# A8137M register map
Vendor: Amiccom Electronics Co., Ltd.; Series: A8137M; File version: 1.0
CPU: CM0 r0p0, little endian, no MPU, no FPU, 2 interrupt priority bits
Registers are 32-bit, read-write, reset 0x0 unless marked. A register's access mark holds for its fields unless they carry their own. Offsets are from the block's base; [hi:lo] are bit positions; {n}, {i} and the like mark numbered series.

## GPIO0 — General Purpose I/O
Base 0x40010000
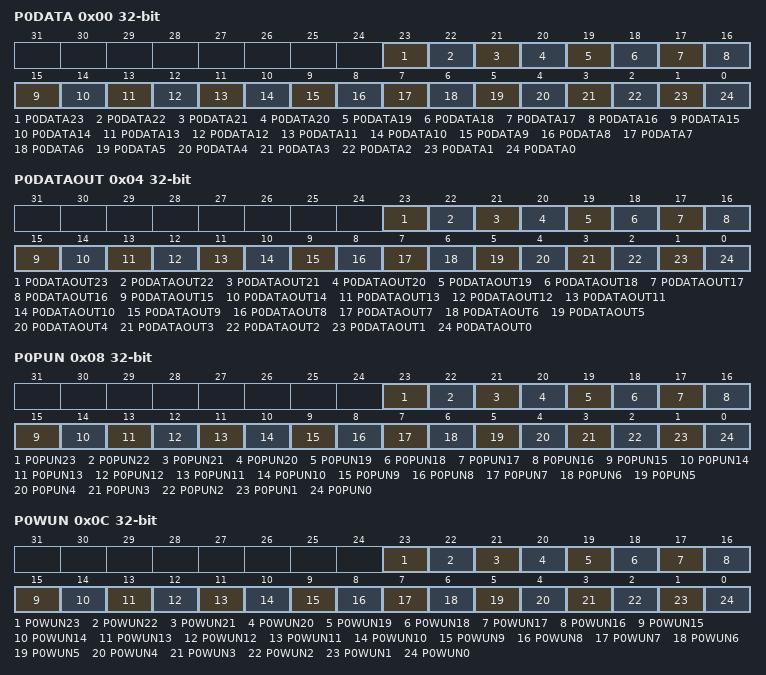
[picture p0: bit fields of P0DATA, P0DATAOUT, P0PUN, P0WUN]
0x00 P0DATA — Port 0 Data Register
  [23] P0DATA23 — Data of GPIO0.23
    0=GPIO0.23 is 0; 1=GPIO0.23 is 1
  [22] P0DATA22 — Data of GPIO0.22
    0=GPIO0.22 is 0; 1=GPIO0.22 is 1
  [21] P0DATA21 — Data of GPIO0.21
    0=GPIO0.21 is 0; 1=GPIO0.21 is 1
  [20] P0DATA20 — Data of GPIO0.20
    0=GPIO0.20 is 0; 1=GPIO0.20 is 1
  [19] P0DATA19 — Data of GPIO0.19
    0=GPIO0.19 is 0; 1=GPIO0.19 is 1
  [18] P0DATA18 — Data of GPIO0.18
    0=GPIO0.18 is 0; 1=GPIO0.18 is 1
  [17] P0DATA17 — Data of GPIO0.17
    0=GPIO0.17 is 0; 1=GPIO0.17 is 1
  [16] P0DATA16 — Data of GPIO0.16
    0=GPIO0.16 is 0; 1=GPIO0.16 is 1
  [15] P0DATA15 — Data of GPIO0.15
    0=GPIO0.15 is 0; 1=GPIO0.15 is 1
  [14] P0DATA14 — Data of GPIO0.14
    0=GPIO0.14 is 0; 1=GPIO0.14 is 1
  [13] P0DATA13 — Data of GPIO0.13
    0=GPIO0.13 is 0; 1=GPIO0.13 is 1
  [12] P0DATA12 — Data of GPIO0.12
    0=GPIO0.12 is 0; 1=GPIO0.12 is 1
  [11] P0DATA11 — Data of GPIO0.11
    0=GPIO0.11 is 0; 1=GPIO0.11 is 1
  [10] P0DATA10 — Data of GPIO0.10
    0=GPIO0.10 is 0; 1=GPIO0.10 is 1
  [9] P0DATA9 — Data of GPIO0.9
    0=GPIO0.9 is 0; 1=GPIO0.9 is 1
  [8] P0DATA8 — Data of GPIO0.8
    0=GPIO0.8 is 0; 1=GPIO0.8 is 1
  [7] P0DATA7 — Data of GPIO0.7
    0=GPIO0.7 is 0; 1=GPIO0.7 is 1
  [6] P0DATA6 — Data of GPIO0.6
    0=GPIO0.6 is 0; 1=GPIO0.6 is 1
  [5] P0DATA5 — Data of GPIO0.5
    0=GPIO0.5 is 0; 1=GPIO0.5 is 1
  [4] P0DATA4 — Data of GPIO0.4
    0=GPIO0.4 is 0; 1=GPIO0.4 is 1
  [3] P0DATA3 — Data of GPIO0.3
    0=GPIO0.3 is 0; 1=GPIO0.3 is 1
  [2] P0DATA2 — Data of GPIO0.2
    0=GPIO0.2 is 0; 1=GPIO0.2 is 1
  [1] P0DATA1 — Data of GPIO0.1
    0=GPIO0.1 is 0; 1=GPIO0.1 is 1
  [0] P0DATA0 — Data of GPIO0.0
    0=GPIO0.0 is 0; 1=GPIO0.0 is 1
0x00 P0DATA_PIN (reset mask 0xFFFFFF) (alternate view of P0DATA) — Port 0 Data Register access by Pin
0x04 P0DATAOUT — Port 0 Data Out Register
  [23] P0DATAOUT23 — Data Out of GPIO0.23
    0=GPIO0.23 is 0; 1=GPIO0.23 is 1
  [22] P0DATAOUT22 — Data Out of GPIO0.22
    0=GPIO0.22 is 0; 1=GPIO0.22 is 1
  [21] P0DATAOUT21 — Data Out of GPIO0.21
    0=GPIO0.21 is 0; 1=GPIO0.21 is 1
  [20] P0DATAOUT20 — Data Out of GPIO0.20
    0=GPIO0.20 is 0; 1=GPIO0.20 is 1
  [19] P0DATAOUT19 — Data Out of GPIO0.19
    0=GPIO0.19 is 0; 1=GPIO0.19 is 1
  [18] P0DATAOUT18 — Data Out of GPIO0.18
    0=GPIO0.18 is 0; 1=GPIO0.18 is 1
  [17] P0DATAOUT17 — Data Out of GPIO0.17
    0=GPIO0.17 is 0; 1=GPIO0.17 is 1
  [16] P0DATAOUT16 — Data Out of GPIO0.16
    0=GPIO0.16 is 0; 1=GPIO0.16 is 1
  [15] P0DATAOUT15 — Data Out of GPIO0.15
    0=GPIO0.15 is 0; 1=GPIO0.15 is 1
  [14] P0DATAOUT14 — Data Out of GPIO0.14
    0=GPIO0.14 is 0; 1=GPIO0.14 is 1
  [13] P0DATAOUT13 — Data Out of GPIO0.13
    0=GPIO0.13 is 0; 1=GPIO0.13 is 1
  [12] P0DATAOUT12 — Data Out of GPIO0.12
    0=GPIO0.12 is 0; 1=GPIO0.12 is 1
  [11] P0DATAOUT11 — Data Out of GPIO0.11
    0=GPIO0.11 is 0; 1=GPIO0.11 is 1
  [10] P0DATAOUT10 — Data Out of GPIO0.10
    0=GPIO0.10 is 0; 1=GPIO0.10 is 1
  [9] P0DATAOUT9 — Data Out of GPIO0.9
    0=GPIO0.9 is 0; 1=GPIO0.9 is 1
  [8] P0DATAOUT8 — Data Out of GPIO0.8
    0=GPIO0.8 is 0; 1=GPIO0.8 is 1
  [7] P0DATAOUT7 — Data Out of GPIO0.7
    0=GPIO0.7 is 0; 1=GPIO0.7 is 1
  [6] P0DATAOUT6 — Data Out of GPIO0.6
    0=GPIO0.6 is 0; 1=GPIO0.6 is 1
  [5] P0DATAOUT5 — Data Out of GPIO0.5
    0=GPIO0.5 is 0; 1=GPIO0.5 is 1
  [4] P0DATAOUT4 — Data Out of GPIO0.4
    0=GPIO0.4 is 0; 1=GPIO0.4 is 1
  [3] P0DATAOUT3 — Data Out of GPIO0.3
    0=GPIO0.3 is 0; 1=GPIO0.3 is 1
  [2] P0DATAOUT2 — Data Out of GPIO0.2
    0=GPIO0.2 is 0; 1=GPIO0.2 is 1
  [1] P0DATAOUT1 — Data Out of GPIO0.1
    0=GPIO0.1 is 0; 1=GPIO0.1 is 1
  [0] P0DATAOUT0 — Data Out of GPIO0.0
    0=GPIO0.0 is 0; 1=GPIO0.0 is 1
0x04 P0DATAOUT_PIN (reset mask 0xFFFFFF) (alternate view of P0DATAOUT) — Port 0 Data Out Register access by Pin
0x08 P0PUN — Port 0 Pull Up Not Register
  [23] P0PUN23 — Pull Up of GPIO0.23
    0=Pull Up of GPIO0.23 is enable; 1=Pull Up of GPIO0.23 is disable
  [22] P0PUN22 — Pull Up of GPIO0.22
    0=Pull Up of GPIO0.22 is enable; 1=Pull Up of GPIO0.22 is disable
  [21] P0PUN21 — Pull Up of GPIO0.21
    0=Pull Up of GPIO0.21 is enable; 1=Pull Up of GPIO0.21 is disable
  [20] P0PUN20 — Pull Up of GPIO0.20
    0=Pull Up of GPIO0.20 is enable; 1=Pull Up of GPIO0.20 is disable
  [19] P0PUN19 — Pull Up of GPIO0.19
    0=Pull Up of GPIO0.19 is enable; 1=Pull Up of GPIO0.19 is disable
  [18] P0PUN18 — Pull Up of GPIO0.18
    0=Pull Up of GPIO0.18 is enable; 1=Pull Up of GPIO0.18 is disable
  [17] P0PUN17 — Pull Up of GPIO0.17
    0=Pull Up of GPIO0.17 is enable; 1=Pull Up of GPIO0.17 is disable
  [16] P0PUN16 — Pull Up of GPIO0.16
    0=Pull Up of GPIO0.16 is enable; 1=Pull Up of GPIO0.16 is disable
  [15] P0PUN15 — Pull Up of GPIO0.15
    0=Pull Up of GPIO0.15 is enable; 1=Pull Up of GPIO0.15 is disable
  [14] P0PUN14 — Pull Up of GPIO0.14
    0=Pull Up of GPIO0.14 is enable; 1=Pull Up of GPIO0.14 is disable
  [13] P0PUN13 — Pull Up of GPIO0.13
    0=Pull Up of GPIO0.13 is enable; 1=Pull Up of GPIO0.13 is disable
  [12] P0PUN12 — Pull Up of GPIO0.12
    0=Pull Up of GPIO0.12 is enable; 1=Pull Up of GPIO0.12 is disable
  [11] P0PUN11 — Pull Up of GPIO0.11
    0=Pull Up of GPIO0.11 is enable; 1=Pull Up of GPIO0.11 is disable
  [10] P0PUN10 — Pull Up of GPIO0.10
    0=Pull Up of GPIO0.10 is enable; 1=Pull Up of GPIO0.10 is disable
  [9] P0PUN9 — Pull Up of GPIO0.9
    0=Pull Up of GPIO0.9 is enable; 1=Pull Up of GPIO0.9 is disable
  [8] P0PUN8 — Pull Up of GPIO0.8
    0=Pull Up of GPIO0.8 is enable; 1=Pull Up of GPIO0.8 is disable
  [7] P0PUN7 — Pull Up of GPIO0.7
    0=Pull Up of GPIO0.7 is enable; 1=Pull Up of GPIO0.7 is disable
  [6] P0PUN6 — Pull Up of GPIO0.6
    0=Pull Up of GPIO0.6 is enable; 1=Pull Up of GPIO0.6 is disable
  [5] P0PUN5 — Pull Up of GPIO0.5
    0=Pull Up of GPIO0.5 is enable; 1=Pull Up of GPIO0.5 is disable
  [4] P0PUN4 — Pull Up of GPIO0.4
    0=Pull Up of GPIO0.4 is enable; 1=Pull Up of GPIO0.4 is disable
  [3] P0PUN3 — Pull Up of GPIO0.3
    0=Pull Up of GPIO0.3 is enable; 1=Pull Up of GPIO0.3 is disable
  [2] P0PUN2 — Pull Up of GPIO0.2
    0=Pull Up of GPIO0.2 is enable; 1=Pull Up of GPIO0.2 is disable
  [1] P0PUN1 — Pull Up of GPIO0.1
    0=Pull Up of GPIO0.1 is enable; 1=Pull Up of GPIO0.1 is disable
  [0] P0PUN0 — Pull Up of GPIO0.0
    0=Pull Up of GPIO0.0 is enable; 1=Pull Up of GPIO0.0 is disable
0x08 P0PUN_PIN (reset mask 0xFFFFFF) (alternate view of P0PUN) — Port 0 Pull Up Not Register access by Pin
0x0C P0WUN — Port 0 Wakeup Enable Not Register
  [23] P0WUN23 — Wakeup of GPIO0.23
    0=Wakeup of GPIO0.23 is enable; 1=Wakeup of GPIO0.23 is disable
  [22] P0WUN22 — Wakeup of GPIO0.22
    0=Wakeup of GPIO0.22 is enable; 1=Wakeup of GPIO0.22 is disable
  [21] P0WUN21 — Wakeup of GPIO0.21
    0=Wakeup of GPIO0.21 is enable; 1=Wakeup of GPIO0.21 is disable
  [20] P0WUN20 — Wakeup of GPIO0.20
    0=Wakeup of GPIO0.20 is enable; 1=Wakeup of GPIO0.20 is disable
  [19] P0WUN19 — Wakeup of GPIO0.19
    0=Wakeup of GPIO0.19 is enable; 1=Wakeup of GPIO0.19 is disable
  [18] P0WUN18 — Wakeup of GPIO0.18
    0=Wakeup of GPIO0.18 is enable; 1=Wakeup of GPIO0.18 is disable
  [17] P0WUN17 — Wakeup of GPIO0.17
    0=Wakeup of GPIO0.17 is enable; 1=Wakeup of GPIO0.17 is disable
  [16] P0WUN16 — Wakeup of GPIO0.16
    0=Wakeup of GPIO0.16 is enable; 1=Wakeup of GPIO0.16 is disable
  [15] P0WUN15 — Wakeup of GPIO0.15
    0=Wakeup of GPIO0.15 is enable; 1=Wakeup of GPIO0.15 is disable
  [14] P0WUN14 — Wakeup of GPIO0.14
    0=Wakeup of GPIO0.14 is enable; 1=Wakeup of GPIO0.14 is disable
  [13] P0WUN13 — Wakeup of GPIO0.13
    0=Wakeup of GPIO0.13 is enable; 1=Wakeup of GPIO0.13 is disable
  [12] P0WUN12 — Wakeup of GPIO0.12
    0=Wakeup of GPIO0.12 is enable; 1=Wakeup of GPIO0.12 is disable
  [11] P0WUN11 — Wakeup of GPIO0.11
    0=Wakeup of GPIO0.11 is enable; 1=Wakeup of GPIO0.11 is disable
  [10] P0WUN10 — Wakeup of GPIO0.10
    0=Wakeup of GPIO0.10 is enable; 1=Wakeup of GPIO0.10 is disable
  [9] P0WUN9 — Wakeup of GPIO0.9
    0=Wakeup of GPIO0.9 is enable; 1=Wakeup of GPIO0.9 is disable
  [8] P0WUN8 — Wakeup of GPIO0.8
    0=Wakeup of GPIO0.8 is enable; 1=Wakeup of GPIO0.8 is disable
  [7] P0WUN7 — Wakeup of GPIO0.7
    0=Wakeup of GPIO0.7 is enable; 1=Wakeup of GPIO0.7 is disable
  [6] P0WUN6 — Wakeup of GPIO0.6
    0=Wakeup of GPIO0.6 is enable; 1=Wakeup of GPIO0.6 is disable
  [5] P0WUN5 — Wakeup of GPIO0.5
    0=Wakeup of GPIO0.5 is enable; 1=Wakeup of GPIO0.5 is disable
  [4] P0WUN4 — Wakeup of GPIO0.4
    0=Wakeup of GPIO0.4 is enable; 1=Wakeup of GPIO0.4 is disable
  [3] P0WUN3 — Wakeup of GPIO0.3
    0=Wakeup of GPIO0.3 is enable; 1=Wakeup of GPIO0.3 is disable
  [2] P0WUN2 — Wakeup of GPIO0.2
    0=Wakeup of GPIO0.2 is enable; 1=Wakeup of GPIO0.2 is disable
  [1] P0WUN1 — Wakeup of GPIO0.1
    0=Wakeup of GPIO0.1 is enable; 1=Wakeup of GPIO0.1 is disable
  [0] P0WUN0 — Wakeup of GPIO0.0
    0=Wakeup of GPIO0.0 is enable; 1=Wakeup of GPIO0.0 is disable
0x0C P0WUN_PIN (reset mask 0xFFFFFF) (alternate view of P0WUN) — Port 0 Wakeup Enable Not Register access by Pin
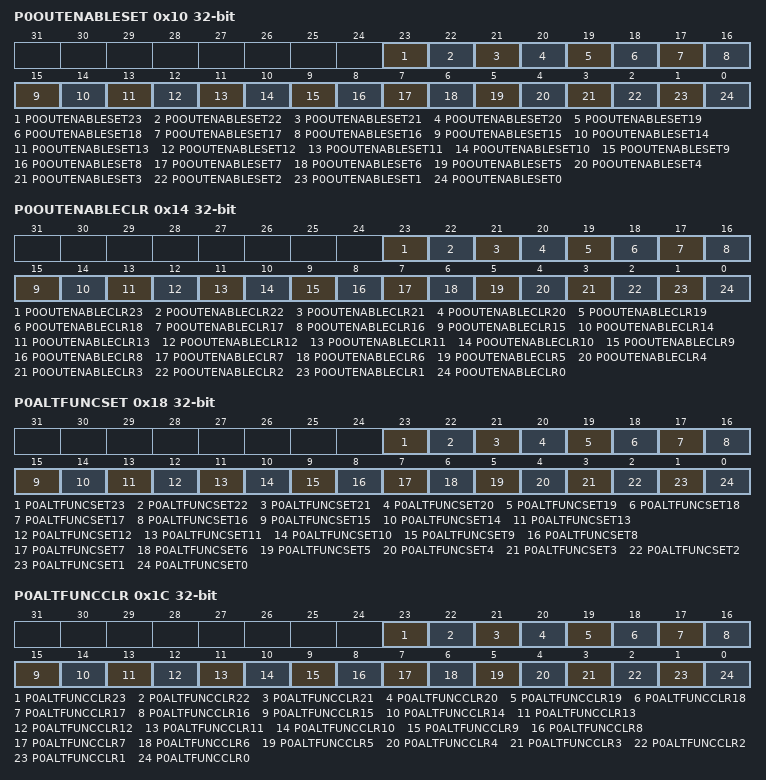
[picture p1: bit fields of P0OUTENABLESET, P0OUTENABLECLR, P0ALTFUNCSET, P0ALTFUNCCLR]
0x10 P0OUTENABLESET — Port 0 Output Enable Set Register
  [23] P0OUTENABLESET23 — Output Enable Set of GPIO0.23
    0=No effect; 1=Output Enable Set of GPIO0.23
  [22] P0OUTENABLESET22 — Output Enable Set of GPIO0.22
    0=No effect; 1=Output Enable Set of GPIO0.22
  [21] P0OUTENABLESET21 — Output Enable Set of GPIO0.21
    0=No effect; 1=Output Enable Set of GPIO0.21
  [20] P0OUTENABLESET20 — Output Enable Set of GPIO0.20
    0=No effect; 1=Output Enable Set of GPIO0.20
  [19] P0OUTENABLESET19 — Output Enable Set of GPIO0.19
    0=No effect; 1=Output Enable Set of GPIO0.19
  [18] P0OUTENABLESET18 — Output Enable Set of GPIO0.18
    0=No effect; 1=Output Enable Set of GPIO0.18
  [17] P0OUTENABLESET17 — Output Enable Set of GPIO0.17
    0=No effect; 1=Output Enable Set of GPIO0.17
  [16] P0OUTENABLESET16 — Output Enable Set of GPIO0.16
    0=No effect; 1=Output Enable Set of GPIO0.16
  [15] P0OUTENABLESET15 — Output Enable Set of GPIO0.15
    0=No effect; 1=Output Enable Set of GPIO0.15
  [14] P0OUTENABLESET14 — Output Enable Set of GPIO0.14
    0=No effect; 1=Output Enable Set of GPIO0.14
  [13] P0OUTENABLESET13 — Output Enable Set of GPIO0.13
    0=No effect; 1=Output Enable Set of GPIO0.13
  [12] P0OUTENABLESET12 — Output Enable Set of GPIO0.12
    0=No effect; 1=Output Enable Set of GPIO0.12
  [11] P0OUTENABLESET11 — Output Enable Set of GPIO0.11
    0=No effect; 1=Output Enable Set of GPIO0.11
  [10] P0OUTENABLESET10 — Output Enable Set of GPIO0.10
    0=No effect; 1=Output Enable Set of GPIO0.10
  [9] P0OUTENABLESET9 — Output Enable Set of GPIO0.9
    0=No effect; 1=Output Enable Set of GPIO0.9
  [8] P0OUTENABLESET8 — Output Enable Set of GPIO0.8
    0=No effect; 1=Output Enable Set of GPIO0.8
  [7] P0OUTENABLESET7 — Output Enable Set of GPIO0.7
    0=No effect; 1=Output Enable Set of GPIO0.7
  [6] P0OUTENABLESET6 — Output Enable Set of GPIO0.6
    0=No effect; 1=Output Enable Set of GPIO0.6
  [5] P0OUTENABLESET5 — Output Enable Set of GPIO0.5
    0=No effect; 1=Output Enable Set of GPIO0.5
  [4] P0OUTENABLESET4 — Output Enable Set of GPIO0.4
    0=No effect; 1=Output Enable Set of GPIO0.4
  [3] P0OUTENABLESET3 — Output Enable Set of GPIO0.3
    0=No effect; 1=Output Enable Set of GPIO0.3
  [2] P0OUTENABLESET2 — Output Enable Set of GPIO0.2
    0=No effect; 1=Output Enable Set of GPIO0.2
  [1] P0OUTENABLESET1 — Output Enable Set of GPIO0.1
    0=No effect; 1=Output Enable Set of GPIO0.1
  [0] P0OUTENABLESET0 — Output Enable Set of GPIO0.0
    0=No effect; 1=Output Enable Set of GPIO0.0
0x14 P0OUTENABLECLR — Port 0 Output Enable Clear Register
  [23] P0OUTENABLECLR23 — Output Enable Clear of GPIO0.23
    0=No effect; 1=Output Enable Clear of GPIO0.23
  [22] P0OUTENABLECLR22 — Output Enable Clear of GPIO0.22
    0=No effect; 1=Output Enable Clear of GPIO0.22
  [21] P0OUTENABLECLR21 — Output Enable Clear of GPIO0.21
    0=No effect; 1=Output Enable Clear of GPIO0.21
  [20] P0OUTENABLECLR20 — Output Enable Clear of GPIO0.20
    0=No effect; 1=Output Enable Clear of GPIO0.20
  [19] P0OUTENABLECLR19 — Output Enable Clear of GPIO0.19
    0=No effect; 1=Output Enable Clear of GPIO0.19
  [18] P0OUTENABLECLR18 — Output Enable Clear of GPIO0.18
    0=No effect; 1=Output Enable Clear of GPIO0.18
  [17] P0OUTENABLECLR17 — Output Enable Clear of GPIO0.17
    0=No effect; 1=Output Enable Clear of GPIO0.17
  [16] P0OUTENABLECLR16 — Output Enable Clear of GPIO0.16
    0=No effect; 1=Output Enable Clear of GPIO0.16
  [15] P0OUTENABLECLR15 — Output Enable Clear of GPIO0.15
    0=No effect; 1=Output Enable Clear of GPIO0.15
  [14] P0OUTENABLECLR14 — Output Enable Clear of GPIO0.14
    0=No effect; 1=Output Enable Clear of GPIO0.14
  [13] P0OUTENABLECLR13 — Output Enable Clear of GPIO0.13
    0=No effect; 1=Output Enable Clear of GPIO0.13
  [12] P0OUTENABLECLR12 — Output Enable Clear of GPIO0.12
    0=No effect; 1=Output Enable Clear of GPIO0.12
  [11] P0OUTENABLECLR11 — Output Enable Clear of GPIO0.11
    0=No effect; 1=Output Enable Clear of GPIO0.11
  [10] P0OUTENABLECLR10 — Output Enable Clear of GPIO0.10
    0=No effect; 1=Output Enable Clear of GPIO0.10
  [9] P0OUTENABLECLR9 — Output Enable Clear of GPIO0.9
    0=No effect; 1=Output Enable Clear of GPIO0.9
  [8] P0OUTENABLECLR8 — Output Enable Clear of GPIO0.8
    0=No effect; 1=Output Enable Clear of GPIO0.8
  [7] P0OUTENABLECLR7 — Output Enable Clear of GPIO0.7
    0=No effect; 1=Output Enable Clear of GPIO0.7
  [6] P0OUTENABLECLR6 — Output Enable Clear of GPIO0.6
    0=No effect; 1=Output Enable Clear of GPIO0.6
  [5] P0OUTENABLECLR5 — Output Enable Clear of GPIO0.5
    0=No effect; 1=Output Enable Clear of GPIO0.5
  [4] P0OUTENABLECLR4 — Output Enable Clear of GPIO0.4
    0=No effect; 1=Output Enable Clear of GPIO0.4
  [3] P0OUTENABLECLR3 — Output Enable Clear of GPIO0.3
    0=No effect; 1=Output Enable Clear of GPIO0.3
  [2] P0OUTENABLECLR2 — Output Enable Clear of GPIO0.2
    0=No effect; 1=Output Enable Clear of GPIO0.2
  [1] P0OUTENABLECLR1 — Output Enable Clear of GPIO0.1
    0=No effect; 1=Output Enable Clear of GPIO0.1
  [0] P0OUTENABLECLR0 — 0 Output Enable Clear of GPIO0.0
    0=No effect; 1=Output enable clear of GPIO0.0
0x18 P0ALTFUNCSET — Port 0 Alternative Function Set Register
  [23] P0ALTFUNCSET23 — Alternative Function Set of GPIO0.23
    0=No effect; 1=Alternative Function Set of GPIO0.23
  [22] P0ALTFUNCSET22 — Alternative Function Set of GPIO0.22
    0=No effect; 1=Alternative Function Set of GPIO0.22
  [21] P0ALTFUNCSET21 — Alternative Function Set of GPIO0.21
    0=No effect; 1=Alternative Function Set of GPIO0.21
  [20] P0ALTFUNCSET20 — Alternative Function Set of GPIO0.20
    0=No effect; 1=Alternative Function Set of GPIO0.20
  [19] P0ALTFUNCSET19 — Alternative Function Set of GPIO0.19
    0=No effect; 1=Alternative Function Set of GPIO0.19
  [18] P0ALTFUNCSET18 — Alternative Function Set of GPIO0.18
    0=No effect; 1=Alternative Function Set of GPIO0.18
  [17] P0ALTFUNCSET17 — Alternative Function Set of GPIO0.17
    0=No effect; 1=Alternative Function Set of GPIO0.17
  [16] P0ALTFUNCSET16 — Alternative Function Set of GPIO0.16
    0=No effect; 1=Alternative Function Set of GPIO0.16
  [15] P0ALTFUNCSET15 — Alternative Function Set of GPIO0.15
    0=No effect; 1=Alternative Function Set of GPIO0.15
  [14] P0ALTFUNCSET14 — Alternative Function Set of GPIO0.14
    0=No effect; 1=Alternative Function Set of GPIO0.14
  [13] P0ALTFUNCSET13 — Alternative Function Set of GPIO0.13
    0=No effect; 1=Alternative Function Set of GPIO0.13
  [12] P0ALTFUNCSET12 — Alternative Function Set of GPIO0.12
    0=No effect; 1=Alternative Function Set of GPIO0.12
  [11] P0ALTFUNCSET11 — Alternative Function Set of GPIO0.11
    0=No effect; 1=Alternative Function Set of GPIO0.11
  [10] P0ALTFUNCSET10 — Alternative Function Set of GPIO0.10
    0=No effect; 1=Alternative Function Set of GPIO0.10
  [9] P0ALTFUNCSET9 — Alternative Function Set of GPIO0.9
    0=No effect; 1=Alternative Function Set of GPIO0.9
  [8] P0ALTFUNCSET8 — Alternative Function Set of GPIO0.8
    0=No effect; 1=Alternative Function Set of GPIO0.8
  [7] P0ALTFUNCSET7 — Alternative Function Set of GPIO0.7
    0=No effect; 1=Alternative Function Set of GPIO0.7
  [6] P0ALTFUNCSET6 — Alternative Function Set of GPIO0.6
    0=No effect; 1=Alternative Function Set of GPIO0.6
  [5] P0ALTFUNCSET5 — Alternative Function Set of GPIO0.5
    0=No effect; 1=Alternative Function Set of GPIO0.5
  [4] P0ALTFUNCSET4 — Alternative Function Set of GPIO0.4
    0=No effect; 1=Alternative Function Set of GPIO0.4
  [3] P0ALTFUNCSET3 — Alternative Function Set of GPIO0.3
    0=No effect; 1=Alternative Function Set of GPIO0.3
  [2] P0ALTFUNCSET2 — Alternative Function Set of GPIO0.2
    0=No effect; 1=Alternative Function Set of GPIO0.2
  [1] P0ALTFUNCSET1 — Alternative Function Set of GPIO0.1
    0=No effect; 1=Alternative Function Set of GPIO0.1
  [0] P0ALTFUNCSET0 — Alternative Function Set of GPIO0.0
    0=No effect; 1=Alternative Function Set of GPIO0.0
0x1C P0ALTFUNCCLR — Port 0 Alternative Function Clear Register
  [23] P0ALTFUNCCLR23 — Alternative Function Clear of GPIO0.23
    0=No effect; 1=Alternative Function Clear of GPIO0.23
  [22] P0ALTFUNCCLR22 — Alternative Function Clear of GPIO0.22
    0=No effect; 1=Alternative Function Clear of GPIO0.22
  [21] P0ALTFUNCCLR21 — Alternative Function Clear of GPIO0.21
    0=No effect; 1=Alternative Function Clear of GPIO0.21
  [20] P0ALTFUNCCLR20 — Alternative Function Clear of GPIO0.20
    0=No effect; 1=Alternative Function Clear of GPIO0.20
  [19] P0ALTFUNCCLR19 — Alternative Function Clear of GPIO0.19
    0=No effect; 1=Alternative Function Clear of GPIO0.19
  [18] P0ALTFUNCCLR18 — Alternative Function Clear of GPIO0.18
    0=No effect; 1=Alternative Function Clear of GPIO0.18
  [17] P0ALTFUNCCLR17 — Alternative Function Clear of GPIO0.17
    0=No effect; 1=Alternative Function Clear of GPIO0.17
  [16] P0ALTFUNCCLR16 — Alternative Function Clear of GPIO0.16
    0=No effect; 1=Alternative Function Clear of GPIO0.16
  [15] P0ALTFUNCCLR15 — Alternative Function Clear of GPIO0.15
    0=No effect; 1=Alternative Function Clear of GPIO0.15
  [14] P0ALTFUNCCLR14 — Alternative Function Clear of GPIO0.14
    0=No effect; 1=Alternative Function Clear of GPIO0.14
  [13] P0ALTFUNCCLR13 — Alternative Function Clear of GPIO0.13
    0=No effect; 1=Alternative Function Clear of GPIO0.13
  [12] P0ALTFUNCCLR12 — Alternative Function Clear of GPIO0.12
    0=No effect; 1=Alternative Function Clear of GPIO0.12
  [11] P0ALTFUNCCLR11 — Alternative Function Clear of GPIO0.11
    0=No effect; 1=Alternative Function Clear of GPIO0.11
  [10] P0ALTFUNCCLR10 — Alternative Function Clear of GPIO0.10
    0=No effect; 1=Alternative Function Clear of GPIO0.10
  [9] P0ALTFUNCCLR9 — Alternative Function Clear of GPIO0.9
    0=No effect; 1=Alternative Function Clear of GPIO0.9
  [8] P0ALTFUNCCLR8 — Alternative Function Clear of GPIO0.8
    0=No effect; 1=Alternative Function Clear of GPIO0.8
  [7] P0ALTFUNCCLR7 — Alternative Function Clear of GPIO0.7
    0=No effect; 1=Alternative Function Clear of GPIO0.7
  [6] P0ALTFUNCCLR6 — Alternative Function Clear of GPIO0.6
    0=No effect; 1=Alternative Function Clear of GPIO0.6
  [5] P0ALTFUNCCLR5 — Alternative Function Clear of GPIO0.5
    0=No effect; 1=Alternative Function Clear of GPIO0.5
  [4] P0ALTFUNCCLR4 — Alternative Function Clear of GPIO0.4
    0=No effect; 1=Alternative Function Clear of GPIO0.4
  [3] P0ALTFUNCCLR3 — Alternative Function Clear of GPIO0.3
    0=No effect; 1=Alternative Function Clear of GPIO0.3
  [2] P0ALTFUNCCLR2 — Alternative Function Clear of GPIO0.2
    0=No effect; 1=Alternative Function Clear of GPIO0.2
  [1] P0ALTFUNCCLR1 — Alternative Function Clear of GPIO0.1
    0=No effect; 1=Alternative Function Clear of GPIO0.1
  [0] P0ALTFUNCCLR0 — Alternative Function Clear of GPIO0.0
    0=No effect; 1=Alternative Function Clear of GPIO0.0
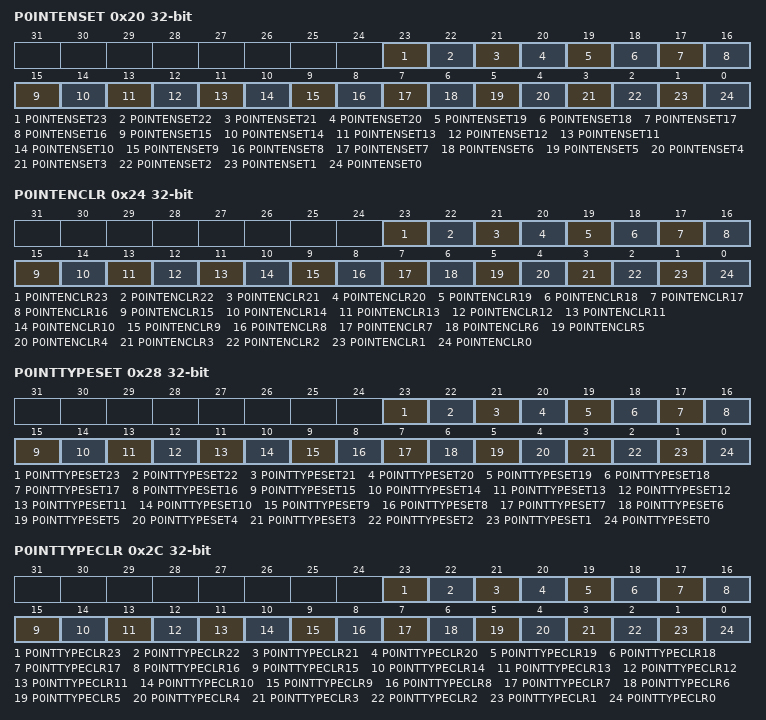
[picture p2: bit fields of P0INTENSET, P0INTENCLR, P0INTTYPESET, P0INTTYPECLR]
0x20 P0INTENSET — Port 0 Interrupt Enable Set Register
  [23] P0INTENSET23 — Interrupt Enable Set of GPIO0.23
    0=No effect; 1=Interrupt Enable Set of GPIO0.23
  [22] P0INTENSET22 — Interrupt Enable Set of GPIO0.22
    0=No effect; 1=Interrupt Enable Set of GPIO0.22
  [21] P0INTENSET21 — Interrupt Enable Set of GPIO0.21
    0=No effect; 1=Interrupt Enable Set of GPIO0.21
  [20] P0INTENSET20 — Interrupt Enable Set of GPIO0.20
    0=No effect; 1=Interrupt Enable Set of GPIO0.20
  [19] P0INTENSET19 — Interrupt Enable Set of GPIO0.19
    0=No effect; 1=Interrupt Enable Set of GPIO0.19
  [18] P0INTENSET18 — Interrupt Enable Set of GPIO0.18
    0=No effect; 1=Interrupt Enable Set of GPIO0.18
  [17] P0INTENSET17 — Interrupt Enable Set of GPIO0.17
    0=No effect; 1=Interrupt Enable Set of GPIO0.17
  [16] P0INTENSET16 — Interrupt Enable Set of GPIO0.16
    0=No effect; 1=Interrupt Enable Set of GPIO0.16
  [15] P0INTENSET15 — Interrupt Enable Set of GPIO0.15
    0=No effect; 1=Interrupt Enable Set of GPIO0.15
  [14] P0INTENSET14 — Interrupt Enable Set of GPIO0.14
    0=No effect; 1=Interrupt Enable Set of GPIO0.14
  [13] P0INTENSET13 — Interrupt Enable Set of GPIO0.13
    0=No effect; 1=Interrupt Enable Set of GPIO0.13
  [12] P0INTENSET12 — Interrupt Enable Set of GPIO0.12
    0=No effect; 1=Interrupt Enable Set of GPIO0.12
  [11] P0INTENSET11 — Interrupt Enable Set of GPIO0.11
    0=No effect; 1=Interrupt Enable Set of GPIO0.11
  [10] P0INTENSET10 — Interrupt Enable Set of GPIO0.10
    0=No effect; 1=Interrupt Enable Set of GPIO0.10
  [9] P0INTENSET9 — Interrupt Enable Set of GPIO0.9
    0=No effect; 1=Interrupt Enable Set of GPIO0.9
  [8] P0INTENSET8 — Interrupt Enable Set of GPIO0.8
    0=No effect; 1=Interrupt Enable Set of GPIO0.8
  [7] P0INTENSET7 — Interrupt Enable Set of GPIO0.7
    0=No effect; 1=Interrupt Enable Set of GPIO0.7
  [6] P0INTENSET6 — Interrupt Enable Set of GPIO0.6
    0=No effect; 1=Interrupt Enable Set of GPIO0.6
  [5] P0INTENSET5 — Interrupt Enable Set of GPIO0.5
    0=No effect; 1=Interrupt Enable Set of GPIO0.5
  [4] P0INTENSET4 — Interrupt Enable Set of GPIO0.4
    0=No effect; 1=Interrupt Enable Set of GPIO0.4
  [3] P0INTENSET3 — Interrupt Enable Set of GPIO0.3
    0=No effect; 1=Interrupt Enable Set of GPIO0.3
  [2] P0INTENSET2 — Interrupt Enable Set of GPIO0.2
    0=No effect; 1=Interrupt Enable Set of GPIO0.2
  [1] P0INTENSET1 — Interrupt Enable Set of GPIO0.1
    0=No effect; 1=Interrupt Enable Set of GPIO0.1
  [0] P0INTENSET0 — Interrupt Enable Set of GPIO0.0
    0=No effect; 1=Interrupt Enable Set of GPIO0.0
0x24 P0INTENCLR — Port 0 Interrupt Enable Clear Register
  [23] P0INTENCLR23 — Interrupt Enable Clear of GPIO0.23
    0=No effect; 1=Interrupt Enable Clear of GPIO0.23
  [22] P0INTENCLR22 — Interrupt Enable Clear of GPIO0.22
    0=No effect; 1=Interrupt Enable Clear of GPIO0.22
  [21] P0INTENCLR21 — Interrupt Enable Clear of GPIO0.21
    0=No effect; 1=Interrupt Enable Clear of GPIO0.21
  [20] P0INTENCLR20 — Interrupt Enable Clear of GPIO0.20
    0=No effect; 1=Interrupt Enable Clear of GPIO0.20
  [19] P0INTENCLR19 — Interrupt Enable Clear of GPIO0.19
    0=No effect; 1=Interrupt Enable Clear of GPIO0.19
  [18] P0INTENCLR18 — Interrupt Enable Clear of GPIO0.18
    0=No effect; 1=Interrupt Enable Clear of GPIO0.18
  [17] P0INTENCLR17 — Interrupt Enable Clear of GPIO0.17
    0=No effect; 1=Interrupt Enable Clear of GPIO0.17
  [16] P0INTENCLR16 — Interrupt Enable Clear of GPIO0.16
    0=No effect; 1=Interrupt Enable Clear of GPIO0.16
  [15] P0INTENCLR15 — Interrupt Enable Clear of GPIO0.15
    0=No effect; 1=Interrupt Enable Clear of GPIO0.15
  [14] P0INTENCLR14 — Interrupt Enable Clear of GPIO0.14
    0=No effect; 1=Interrupt Enable Clear of GPIO0.14
  [13] P0INTENCLR13 — Interrupt Enable Clear of GPIO0.13
    0=No effect; 1=Interrupt Enable Clear of GPIO0.13
  [12] P0INTENCLR12 — Interrupt Enable Clear of GPIO0.12
    0=No effect; 1=Interrupt Enable Clear of GPIO0.12
  [11] P0INTENCLR11 — Interrupt Enable Clear of GPIO0.11
    0=No effect; 1=Interrupt Enable Clear of GPIO0.11
  [10] P0INTENCLR10 — Interrupt Enable Clear of GPIO0.10
    0=No effect; 1=Interrupt Enable Clear of GPIO0.10
  [9] P0INTENCLR9 — Interrupt Enable Clear of GPIO0.9
    0=No effect; 1=Interrupt Enable Clear of GPIO0.9
  [8] P0INTENCLR8 — Interrupt Enable Clear of GPIO0.8
    0=No effect; 1=Interrupt Enable Clear of GPIO0.8
  [7] P0INTENCLR7 — Interrupt Enable Clear of GPIO0.7
    0=No effect; 1=Interrupt Enable Clear of GPIO0.7
  [6] P0INTENCLR6 — Interrupt Enable Clear of GPIO0.6
    0=No effect; 1=Interrupt Enable Clear of GPIO0.6
  [5] P0INTENCLR5 — Interrupt Enable Clear of GPIO0.5
    0=No effect; 1=Interrupt Enable Clear of GPIO0.5
  [4] P0INTENCLR4 — Interrupt Enable Clear of GPIO0.4
    0=No effect; 1=Interrupt Enable Clear of GPIO0.4
  [3] P0INTENCLR3 — Interrupt Enable Clear of GPIO0.3
    0=No effect; 1=Interrupt Enable Clear of GPIO0.3
  [2] P0INTENCLR2 — Interrupt Enable Clear of GPIO0.2
    0=No effect; 1=Interrupt Enable Clear of GPIO0.2
  [1] P0INTENCLR1 — Interrupt Enable Clear of GPIO0.1
    0=No effect; 1=Interrupt Enable Clear of GPIO0.1
  [0] P0INTENCLR0 — Interrupt Enable Clear of GPIO0.0
    0=No effect; 1=Interrupt Enable Clear of GPIO0.0
0x28 P0INTTYPESET — Port 0 Interrupt Type Set Register
  [23] P0INTTYPESET23 — Interrupt type set (interrupt by edge) of GPIO0.23
    0=No effect; 1=Interrupt type set (interrupt by edge) of GPIO0.23
  [22] P0INTTYPESET22 — Interrupt type set (interrupt by edge) of GPIO0.22
    0=No effect; 1=Interrupt type set (interrupt by edge) of GPIO0.22
  [21] P0INTTYPESET21 — Interrupt type set (interrupt by edge) of GPIO0.21
    0=No effect; 1=Interrupt type set (interrupt by edge) of GPIO0.21
  [20] P0INTTYPESET20 — Interrupt type set (interrupt by edge) of GPIO0.20
    0=No effect; 1=Interrupt type set (interrupt by edge) of GPIO0.20
  [19] P0INTTYPESET19 — Interrupt type set (interrupt by edge) of GPIO0.19
    0=No effect; 1=Interrupt type set (interrupt by edge) of GPIO0.19
  [18] P0INTTYPESET18 — Interrupt type set (interrupt by edge) of GPIO0.18
    0=No effect; 1=Interrupt type set (interrupt by edge) of GPIO0.18
  [17] P0INTTYPESET17 — Interrupt type set (interrupt by edge) of GPIO0.17
    0=No effect; 1=Interrupt type set (interrupt by edge) of GPIO0.17
  [16] P0INTTYPESET16 — Interrupt type set (interrupt by edge) of GPIO0.16
    0=No effect; 1=Interrupt type set (interrupt by edge) of GPIO0.16
  [15] P0INTTYPESET15 — Interrupt type set (interrupt by edge) of GPIO0.15
    0=No effect; 1=Interrupt type set (interrupt by edge) of GPIO0.15
  [14] P0INTTYPESET14 — Interrupt type set (interrupt by edge) of GPIO0.14
    0=No effect; 1=Interrupt type set (interrupt by edge) of GPIO0.14
  [13] P0INTTYPESET13 — Interrupt type set (interrupt by edge) of GPIO0.13
    0=No effect; 1=Interrupt type set (interrupt by edge) of GPIO0.13
  [12] P0INTTYPESET12 — Interrupt type set (interrupt by edge) of GPIO0.12
    0=No effect; 1=Interrupt type set (interrupt by edge) of GPIO0.12
  [11] P0INTTYPESET11 — Interrupt type set (interrupt by edge) of GPIO0.11
    0=No effect; 1=Interrupt type set (interrupt by edge) of GPIO0.11
  [10] P0INTTYPESET10 — Interrupt type set (interrupt by edge) of GPIO0.10
    0=No effect; 1=Interrupt type set (interrupt by edge) of GPIO0.10
  [9] P0INTTYPESET9 — Interrupt type set (interrupt by edge) of GPIO0.9
    0=No effect; 1=Interrupt type set (interrupt by edge) of GPIO0.9
  [8] P0INTTYPESET8 — Interrupt type set (interrupt by edge) of GPIO0.8
    0=No effect; 1=Interrupt type set (interrupt by edge) of GPIO0.8
  [7] P0INTTYPESET7 — Interrupt type set (interrupt by edge) of GPIO0.7
    0=No effect; 1=Interrupt type set (interrupt by edge) of GPIO0.7
  [6] P0INTTYPESET6 — Interrupt type set (interrupt by edge) of GPIO0.6
    0=No effect; 1=Interrupt type set (interrupt by edge) of GPIO0.6
  [5] P0INTTYPESET5 — Interrupt type set (interrupt by edge) of GPIO0.5
    0=No effect; 1=Interrupt type set (interrupt by edge) of GPIO0.5
  [4] P0INTTYPESET4 — Interrupt type set (interrupt by edge) of GPIO0.4
    0=No effect; 1=Interrupt type set (interrupt by edge) of GPIO0.4
  [3] P0INTTYPESET3 — Interrupt type set (interrupt by edge) of GPIO0.3
    0=No effect; 1=Interrupt type set (interrupt by edge) of GPIO0.3
  [2] P0INTTYPESET2 — Interrupt type set (interrupt by edge) of GPIO0.2
    0=No effect; 1=Interrupt type set (interrupt by edge) of GPIO0.2
  [1] P0INTTYPESET1 — Interrupt type set (interrupt by edge) of GPIO0.1
    0=No effect; 1=Interrupt type set (interrupt by edge) of GPIO0.1
  [0] P0INTTYPESET0 — Interrupt type set (interrupt by edge) of GPIO0.0
    0=No effect; 1=Interrupt type set (interrupt by edge) of GPIO0.0
0x2C P0INTTYPECLR — Port 0 Interrupt Type Clear Register
  [23] P0INTTYPECLR23 — Interrupt type clean (interrupt by level) of GPIO0.23
    0=No effect; 1=Interrupt type clean (interrupt by level) of GPIO0.23
  [22] P0INTTYPECLR22 — Interrupt type clean (interrupt by level) of GPIO0.22
    0=No effect; 1=Interrupt type clean (interrupt by level) of GPIO0.22
  [21] P0INTTYPECLR21 — Interrupt type clean (interrupt by level) of GPIO0.21
    0=No effect; 1=Interrupt type clean (interrupt by level) of GPIO0.21
  [20] P0INTTYPECLR20 — Interrupt type clean (interrupt by level) of GPIO0.20
    0=No effect; 1=Interrupt type clean (interrupt by level) of GPIO0.20
  [19] P0INTTYPECLR19 — Interrupt type clean (interrupt by level) of GPIO0.19
    0=No effect; 1=Interrupt type clean (interrupt by level) of GPIO0.19
  [18] P0INTTYPECLR18 — Interrupt type clean (interrupt by level) of GPIO0.18
    0=No effect; 1=Interrupt type clean (interrupt by level) of GPIO0.18
  [17] P0INTTYPECLR17 — Interrupt type clean (interrupt by level) of GPIO0.17
    0=No effect; 1=Interrupt type clean (interrupt by level) of GPIO0.17
  [16] P0INTTYPECLR16 — Interrupt type clean (interrupt by level) of GPIO0.16
    0=No effect; 1=Interrupt type clean (interrupt by level) of GPIO0.16
  [15] P0INTTYPECLR15 — Interrupt type clean (interrupt by level) of GPIO0.15
    0=No effect; 1=Interrupt type clean (interrupt by level) of GPIO0.15
  [14] P0INTTYPECLR14 — Interrupt type clean (interrupt by level) of GPIO0.14
    0=No effect; 1=Interrupt type clean (interrupt by level) of GPIO0.14
  [13] P0INTTYPECLR13 — Interrupt type clean (interrupt by level) of GPIO0.13
    0=No effect; 1=Interrupt type clean (interrupt by level) of GPIO0.13
  [12] P0INTTYPECLR12 — Interrupt type clean (interrupt by level) of GPIO0.12
    0=No effect; 1=Interrupt type clean (interrupt by level) of GPIO0.12
  [11] P0INTTYPECLR11 — Interrupt type clean (interrupt by level) of GPIO0.11
    0=No effect; 1=Interrupt type clean (interrupt by level) of GPIO0.11
  [10] P0INTTYPECLR10 — Interrupt type clean (interrupt by level) of GPIO0.10
    0=No effect; 1=Interrupt type clean (interrupt by level) of GPIO0.10
  [9] P0INTTYPECLR9 — Interrupt type clean (interrupt by level) of GPIO0.9
    0=No effect; 1=Interrupt type clean (interrupt by level) of GPIO0.9
  [8] P0INTTYPECLR8 — Interrupt type clean (interrupt by level) of GPIO0.8
    0=No effect; 1=Interrupt type clean (interrupt by level) of GPIO0.8
  [7] P0INTTYPECLR7 — Interrupt type clean (interrupt by level) of GPIO0.7
    0=No effect; 1=Interrupt type clean (interrupt by level) of GPIO0.7
  [6] P0INTTYPECLR6 — Interrupt type clean (interrupt by level) of GPIO0.6
    0=No effect; 1=Interrupt type clean (interrupt by level) of GPIO0.6
  [5] P0INTTYPECLR5 — Interrupt type clean (interrupt by level) of GPIO0.5
    0=No effect; 1=Interrupt type clean (interrupt by level) of GPIO0.5
  [4] P0INTTYPECLR4 — Interrupt type clean (interrupt by level) of GPIO0.4
    0=No effect; 1=Interrupt type clean (interrupt by level) of GPIO0.4
  [3] P0INTTYPECLR3 — Interrupt type clean (interrupt by level) of GPIO0.3
    0=No effect; 1=Interrupt type clean (interrupt by level) of GPIO0.3
  [2] P0INTTYPECLR2 — Interrupt type clean (interrupt by level) of GPIO0.2
    0=No effect; 1=Interrupt type clean (interrupt by level) of GPIO0.2
  [1] P0INTTYPECLR1 — Interrupt type clean (interrupt by level) of GPIO0.1
    0=No effect; 1=Interrupt type clean (interrupt by level) of GPIO0.1
  [0] P0INTTYPECLR0 — Interrupt type clean (interrupt by level) of GPIO0.0
    0=No effect; 1=Interrupt type clean (interrupt by level) of GPIO0.0
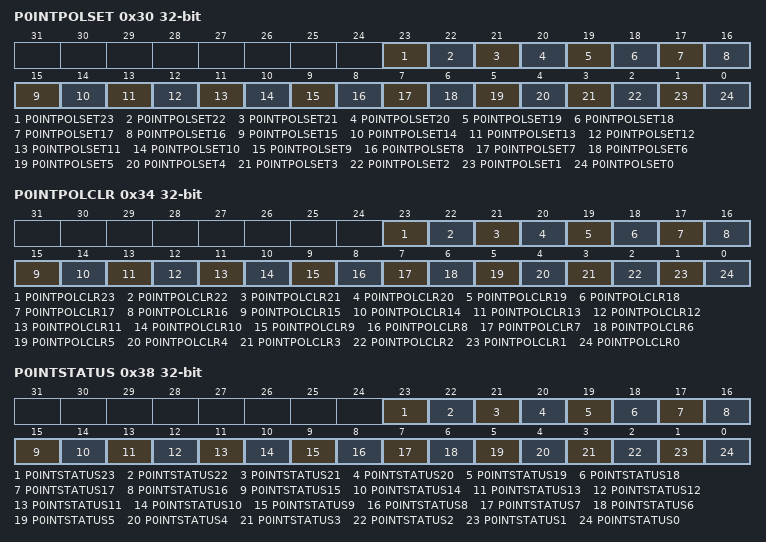
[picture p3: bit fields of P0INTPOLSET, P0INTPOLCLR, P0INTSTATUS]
0x30 P0INTPOLSET — Port 0 Interrupt Polarity Set Register
  [23] P0INTPOLSET23 — Interrupt Polarity-level set (high level or rising edge) of GPIO0.23
    0=No effect; 1=Interrupt Polarity-level set (high level or rising edge) of GPIO0.23
  [22] P0INTPOLSET22 — Interrupt Polarity-level set (high level or rising edge) of GPIO0.22
    0=No effect; 1=Interrupt Polarity-level set (high level or rising edge) of GPIO0.22
  [21] P0INTPOLSET21 — Interrupt Polarity-level set (high level or rising edge) of GPIO0.21
    0=No effect; 1=Interrupt Polarity-level set (high level or rising edge) of GPIO0.21
  [20] P0INTPOLSET20 — Interrupt Polarity-level set (high level or rising edge) of GPIO0.20
    0=No effect; 1=Interrupt Polarity-level set (high level or rising edge) of GPIO0.20
  [19] P0INTPOLSET19 — Interrupt Polarity-level set (high level or rising edge) of GPIO0.19
    0=No effect; 1=Interrupt Polarity-level set (high level or rising edge) of GPIO0.19
  [18] P0INTPOLSET18 — Interrupt Polarity-level set (high level or rising edge) of GPIO0.18
    0=No effect; 1=Interrupt Polarity-level set (high level or rising edge) of GPIO0.18
  [17] P0INTPOLSET17 — Interrupt Polarity-level set (high level or rising edge) of GPIO0.17
    0=No effect; 1=Interrupt Polarity-level set (high level or rising edge) of GPIO0.17
  [16] P0INTPOLSET16 — Interrupt Polarity-level set (high level or rising edge) of GPIO0.16
    0=No effect; 1=Interrupt Polarity-level set (high level or rising edge) of GPIO0.16
  [15] P0INTPOLSET15 — Interrupt Polarity-level set (high level or rising edge) of GPIO0.15
    0=No effect; 1=Interrupt Polarity-level set (high level or rising edge) of GPIO0.15
  [14] P0INTPOLSET14 — Interrupt Polarity-level set (high level or rising edge) of GPIO0.14
    0=No effect; 1=Interrupt Polarity-level set (high level or rising edge) of GPIO0.14
  [13] P0INTPOLSET13 — Interrupt Polarity-level set (high level or rising edge) of GPIO0.13
    0=No effect; 1=Interrupt Polarity-level set (high level or rising edge) of GPIO0.13
  [12] P0INTPOLSET12 — Interrupt Polarity-level set (high level or rising edge) of GPIO0.12
    0=No effect; 1=Interrupt Polarity-level set (high level or rising edge) of GPIO0.12
  [11] P0INTPOLSET11 — Interrupt Polarity-level set (high level or rising edge) of GPIO0.11
    0=No effect; 1=Interrupt Polarity-level set (high level or rising edge) of GPIO0.11
  [10] P0INTPOLSET10 — Interrupt Polarity-level set (high level or rising edge) of GPIO0.10
    0=No effect; 1=Interrupt Polarity-level set (high level or rising edge) of GPIO0.10
  [9] P0INTPOLSET9 — Interrupt Polarity-level set (high level or rising edge) of GPIO0.9
    0=No effect; 1=Interrupt Polarity-level set (high level or rising edge) of GPIO0.9
  [8] P0INTPOLSET8 — Interrupt Polarity-level set (high level or rising edge) of GPIO0.8
    0=No effect; 1=Interrupt Polarity-level set (high level or rising edge) of GPIO0.8
  [7] P0INTPOLSET7 — Interrupt Polarity-level set (high level or rising edge) of GPIO0.7
    0=No effect; 1=Interrupt Polarity-level set (high level or rising edge) of GPIO0.7
  [6] P0INTPOLSET6 — Interrupt Polarity-level set (high level or rising edge) of GPIO0.6
    0=No effect; 1=Interrupt Polarity-level set (high level or rising edge) of GPIO0.6
  [5] P0INTPOLSET5 — Interrupt Polarity-level set (high level or rising edge) of GPIO0.5
    0=No effect; 1=Interrupt Polarity-level set (high level or rising edge) of GPIO0.5
  [4] P0INTPOLSET4 — Interrupt Polarity-level set (high level or rising edge) of GPIO0.4
    0=No effect; 1=Interrupt Polarity-level set (high level or rising edge) of GPIO0.4
  [3] P0INTPOLSET3 — Interrupt Polarity-level set (high level or rising edge) of GPIO0.3
    0=No effect; 1=Interrupt Polarity-level set (high level or rising edge) of GPIO0.3
  [2] P0INTPOLSET2 — Interrupt Polarity-level set (high level or rising edge) of GPIO0.2
    0=No effect; 1=Interrupt Polarity-level set (high level or rising edge) of GPIO0.2
  [1] P0INTPOLSET1 — Interrupt Polarity-level set (high level or rising edge) of GPIO0.1
    0=No effect; 1=Interrupt Polarity-level set (high level or rising edge) of GPIO0.1
  [0] P0INTPOLSET0 — Interrupt Polarity-level set (high level or rising edge) of GPIO0.0
    0=No effect; 1=Interrupt Polarity-level set (high level or rising edge) of GPIO0.0
0x34 P0INTPOLCLR — Port 0 Interrupt Polarity Clear Register
  [23] P0INTPOLCLR23 — Interrupt Polarity-level clean (low level or falling edge) of GPIO0.23
    0=No effect; 1=Interrupt Polarity-level clean (low level or falling edge) of GPIO0.23
  [22] P0INTPOLCLR22 — Interrupt Polarity-level clean (low level or falling edge) of GPIO0.22
    0=No effect; 1=Interrupt Polarity-level clean (low level or falling edge) of GPIO0.22
  [21] P0INTPOLCLR21 — Interrupt Polarity-level clean (low level or falling edge) of GPIO0.21
    0=No effect; 1=Interrupt Polarity-level clean (low level or falling edge) of GPIO0.21
  [20] P0INTPOLCLR20 — Interrupt Polarity-level clean (low level or falling edge) of GPIO0.20
    0=No effect; 1=Interrupt Polarity-level clean (low level or falling edge) of GPIO0.20
  [19] P0INTPOLCLR19 — Interrupt Polarity-level clean (low level or falling edge) of GPIO0.19
    0=No effect; 1=Interrupt Polarity-level clean (low level or falling edge) of GPIO0.19
  [18] P0INTPOLCLR18 — Interrupt Polarity-level clean (low level or falling edge) of GPIO0.18
    0=No effect; 1=Interrupt Polarity-level clean (low level or falling edge) of GPIO0.18
  [17] P0INTPOLCLR17 — Interrupt Polarity-level clean (low level or falling edge) of GPIO0.17
    0=No effect; 1=Interrupt Polarity-level clean (low level or falling edge) of GPIO0.17
  [16] P0INTPOLCLR16 — Interrupt Polarity-level clean (low level or falling edge) of GPIO0.16
    0=No effect; 1=Interrupt Polarity-level clean (low level or falling edge) of GPIO0.16
  [15] P0INTPOLCLR15 — Interrupt Polarity-level clean (low level or falling edge) of GPIO0.15
    0=No effect; 1=Interrupt Polarity-level clean (low level or falling edge) of GPIO0.15
  [14] P0INTPOLCLR14 — Interrupt Polarity-level clean (low level or falling edge) of GPIO0.14
    0=No effect; 1=Interrupt Polarity-level clean (low level or falling edge) of GPIO0.14
  [13] P0INTPOLCLR13 — Interrupt Polarity-level clean (low level or falling edge) of GPIO0.13
    0=No effect; 1=Interrupt Polarity-level clean (low level or falling edge) of GPIO0.13
  [12] P0INTPOLCLR12 — Interrupt Polarity-level clean (low level or falling edge) of GPIO0.12
    0=No effect; 1=Interrupt Polarity-level clean (low level or falling edge) of GPIO0.12
  [11] P0INTPOLCLR11 — Interrupt Polarity-level clean (low level or falling edge) of GPIO0.11
    0=No effect; 1=Interrupt Polarity-level clean (low level or falling edge) of GPIO0.11
  [10] P0INTPOLCLR10 — Interrupt Polarity-level clean (low level or falling edge) of GPIO0.10
    0=No effect; 1=Interrupt Polarity-level clean (low level or falling edge) of GPIO0.10
  [9] P0INTPOLCLR9 — Interrupt Polarity-level clean (low level or falling edge) of GPIO0.9
    0=No effect; 1=Interrupt Polarity-level clean (low level or falling edge) of GPIO0.9
  [8] P0INTPOLCLR8 — Interrupt Polarity-level clean (low level or falling edge) of GPIO0.8
    0=No effect; 1=Interrupt Polarity-level clean (low level or falling edge) of GPIO0.8
  [7] P0INTPOLCLR7 — Interrupt Polarity-level clean (low level or falling edge) of GPIO0.7
    0=No effect; 1=Interrupt Polarity-level clean (low level or falling edge) of GPIO0.7
  [6] P0INTPOLCLR6 — Interrupt Polarity-level clean (low level or falling edge) of GPIO0.6
    0=No effect; 1=Interrupt Polarity-level clean (low level or falling edge) of GPIO0.6
  [5] P0INTPOLCLR5 — Interrupt Polarity-level clean (low level or falling edge) of GPIO0.5
    0=No effect; 1=Interrupt Polarity-level clean (low level or falling edge) of GPIO0.5
  [4] P0INTPOLCLR4 — Interrupt Polarity-level clean (low level or falling edge) of GPIO0.4
    0=No effect; 1=Interrupt Polarity-level clean (low level or falling edge) of GPIO0.4
  [3] P0INTPOLCLR3 — Interrupt Polarity-level clean (low level or falling edge) of GPIO0.3
    0=No effect; 1=Interrupt Polarity-level clean (low level or falling edge) of GPIO0.3
  [2] P0INTPOLCLR2 — Interrupt Polarity-level clean (low level or falling edge) of GPIO0.2
    0=No effect; 1=Interrupt Polarity-level clean (low level or falling edge) of GPIO0.2
  [1] P0INTPOLCLR1 — Interrupt Polarity-level clean (low level or falling edge) of GPIO0.1
    0=No effect; 1=Interrupt Polarity-level clean (low level or falling edge) of GPIO0.1
  [0] P0INTPOLCLR0 — Interrupt Polarity-level clean (low level or falling edge) of GPIO0.0
    0=No effect; 1=Interrupt Polarity-level clean (low level or falling edge) of GPIO0.0
0x38 P0INTSTATUS — Port 0 Interrupt Request Status Register
  [23] P0INTSTATUS23 — Clear interrupt request status of GPIO0.23
    0=No effect; 1=Clear interrupt request status of GPIO0.23
  [22] P0INTSTATUS22 — Clear interrupt request status of GPIO0.22
    0=No effect; 1=Clear interrupt request status of GPIO0.22
  [21] P0INTSTATUS21 — Clear interrupt request status of GPIO0.21
    0=No effect; 1=Clear interrupt request status of GPIO0.21
  [20] P0INTSTATUS20 — Clear interrupt request status of GPIO0.20
    0=No effect; 1=Clear interrupt request status of GPIO0.20
  [19] P0INTSTATUS19 — Clear interrupt request status of GPIO0.19
    0=No effect; 1=Clear interrupt request status of GPIO0.19
  [18] P0INTSTATUS18 — Clear interrupt request status of GPIO0.18
    0=No effect; 1=Clear interrupt request status of GPIO0.18
  [17] P0INTSTATUS17 — Clear interrupt request status of GPIO0.17
    0=No effect; 1=Clear interrupt request status of GPIO0.17
  [16] P0INTSTATUS16 — Clear interrupt request status of GPIO0.16
    0=No effect; 1=Clear interrupt request status of GPIO0.16
  [15] P0INTSTATUS15 — Clear interrupt request status of GPIO0.15
    0=No effect; 1=Clear interrupt request status of GPIO0.15
  [14] P0INTSTATUS14 — Clear interrupt request status of GPIO0.14
    0=No effect; 1=Clear interrupt request status of GPIO0.14
  [13] P0INTSTATUS13 — Clear interrupt request status of GPIO0.13
    0=No effect; 1=Clear interrupt request status of GPIO0.13
  [12] P0INTSTATUS12 — Clear interrupt request status of GPIO0.12
    0=No effect; 1=Clear interrupt request status of GPIO0.12
  [11] P0INTSTATUS11 — Clear interrupt request status of GPIO0.11
    0=No effect; 1=Clear interrupt request status of GPIO0.11
  [10] P0INTSTATUS10 — Clear interrupt request status of GPIO0.10
    0=No effect; 1=Clear interrupt request status of GPIO0.10
  [9] P0INTSTATUS9 — Clear interrupt request status of GPIO0.9
    0=No effect; 1=Clear interrupt request status of GPIO0.9
  [8] P0INTSTATUS8 — Clear interrupt request status of GPIO0.8
    0=No effect; 1=Clear interrupt request status of GPIO0.8
  [7] P0INTSTATUS7 — Clear interrupt request status of GPIO0.7
    0=No effect; 1=Clear interrupt request status of GPIO0.7
  [6] P0INTSTATUS6 — Clear interrupt request status of GPIO0.6
    0=No effect; 1=Clear interrupt request status of GPIO0.6
  [5] P0INTSTATUS5 — Clear interrupt request status of GPIO0.5
    0=No effect; 1=Clear interrupt request status of GPIO0.5
  [4] P0INTSTATUS4 — Clear interrupt request status of GPIO0.4
    0=No effect; 1=Clear interrupt request status of GPIO0.4
  [3] P0INTSTATUS3 — Clear interrupt request status of GPIO0.3
    0=No effect; 1=Clear interrupt request status of GPIO0.3
  [2] P0INTSTATUS2 — Clear interrupt request status of GPIO0.2
    0=No effect; 1=Clear interrupt request status of GPIO0.2
  [1] P0INTSTATUS1 — Clear interrupt request status of GPIO0.1
    0=No effect; 1=Clear interrupt request status of GPIO0.1
  [0] P0INTSTATUS0 — Clear interrupt request status of GPIO0.0
    0=No effect; 1=Clear interrupt request status of GPIO0.0
0x38 P0INTCLEAR wo (reset mask 0xFFFFFF) (alternate view of P0INTSTATUS) — Port 0 Interrupt Request Clear Register
{0x400+4i} LB_MASKED[{i}] (i=0..255) — Lower byte Masked Access Register
{0x800+4i} UB_MASKED[{i}] (i=0..255) — Upper byte Masked Access Register

## Notices in the file
Copyright (C) 2012-2014 ARM Limited. All rights reserved.
Purpose: System Viewer Description (SVD) Example (Schema Version 1.1)
This is a description of a none-existent and incomplete device
for demonstration purposes only.
Redistribution and use in source and binary forms, with or without
modification, are permitted provided that the following conditions are met:
- Redistributions of source code must retain the above copyright
notice, this list of conditions and the following disclaimer.
- Redistributions in binary form must reproduce the above copyright
notice, this list of conditions and the following disclaimer in the
documentation and/or other materials provided with the distribution.
- Neither the name of ARM nor the names of its contributors may be used
to endorse or promote products derived from this software without
specific prior written permission.
THIS SOFTWARE IS PROVIDED BY THE COPYRIGHT HOLDERS AND CONTRIBUTORS "AS IS"
AND ANY EXPRESS OR IMPLIED WARRANTIES, INCLUDING, BUT NOT LIMITED TO, THE
IMPLIED WARRANTIES OF MERCHANTABILITY AND FITNESS FOR A PARTICULAR PURPOSE
ARE DISCLAIMED. IN NO EVENT SHALL COPYRIGHT HOLDERS AND CONTRIBUTORS BE
LIABLE FOR ANY DIRECT, INDIRECT, INCIDENTAL, SPECIAL, EXEMPLARY, OR
CONSEQUENTIAL DAMAGES (INCLUDING, BUT NOT LIMITED TO, PROCUREMENT OF
SUBSTITUTE GOODS OR SERVICES; LOSS OF USE, DATA, OR PROFITS; OR BUSINESS
INTERRUPTION) HOWEVER CAUSED AND ON ANY THEORY OF LIABILITY, WHETHER IN
CONTRACT, STRICT LIABILITY, OR TORT (INCLUDING NEGLIGENCE OR OTHERWISE)
ARISING IN ANY WAY OUT OF THE USE OF THIS SOFTWARE, EVEN IF ADVISED OF THE
POSSIBILITY OF SUCH DAMAGE.
